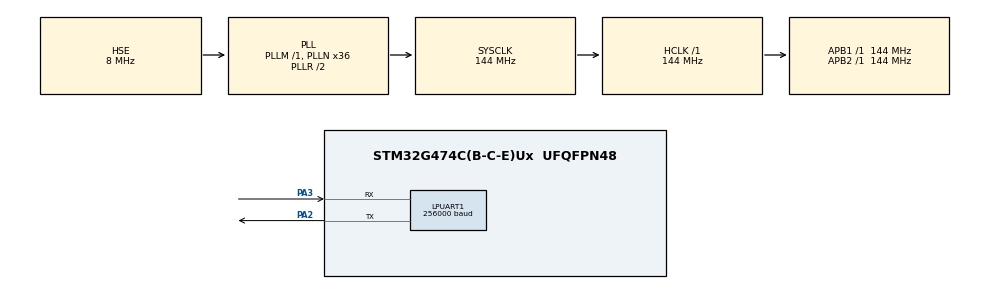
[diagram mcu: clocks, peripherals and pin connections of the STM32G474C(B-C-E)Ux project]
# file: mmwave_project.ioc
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Dma.LPUART1_RX.0.Direction=DMA_PERIPH_TO_MEMORY
Dma.LPUART1_RX.0.EventEnable=DISABLE
Dma.LPUART1_RX.0.Instance=DMA1_Channel1
Dma.LPUART1_RX.0.MemDataAlignment=DMA_MDATAALIGN_BYTE
Dma.LPUART1_RX.0.MemInc=DMA_MINC_ENABLE
Dma.LPUART1_RX.0.Mode=DMA_CIRCULAR
Dma.LPUART1_RX.0.PeriphDataAlignment=DMA_PDATAALIGN_BYTE
Dma.LPUART1_RX.0.PeriphInc=DMA_PINC_DISABLE
Dma.LPUART1_RX.0.Polarity=HAL_DMAMUX_REQ_GEN_RISING
Dma.LPUART1_RX.0.Priority=DMA_PRIORITY_LOW
Dma.LPUART1_RX.0.RequestNumber=1
Dma.LPUART1_RX.0.SignalID=NONE
Dma.LPUART1_RX.0.SyncEnable=DISABLE
Dma.LPUART1_RX.0.SyncPolarity=HAL_DMAMUX_SYNC_NO_EVENT
Dma.LPUART1_RX.0.SyncRequestNumber=1
Dma.LPUART1_RX.0.SyncSignalID=NONE
Dma.LPUART1_TX.1.Direction=DMA_MEMORY_TO_PERIPH
Dma.LPUART1_TX.1.EventEnable=DISABLE
Dma.LPUART1_TX.1.Instance=DMA1_Channel2
Dma.LPUART1_TX.1.MemDataAlignment=DMA_MDATAALIGN_BYTE
Dma.LPUART1_TX.1.MemInc=DMA_MINC_ENABLE
Dma.LPUART1_TX.1.Mode=DMA_NORMAL
Dma.LPUART1_TX.1.PeriphDataAlignment=DMA_PDATAALIGN_BYTE
Dma.LPUART1_TX.1.PeriphInc=DMA_PINC_DISABLE
Dma.LPUART1_TX.1.Polarity=HAL_DMAMUX_REQ_GEN_RISING
Dma.LPUART1_TX.1.Priority=DMA_PRIORITY_LOW
Dma.LPUART1_TX.1.RequestNumber=1
Dma.LPUART1_TX.1.SignalID=NONE
Dma.LPUART1_TX.1.SyncEnable=DISABLE
Dma.LPUART1_TX.1.SyncPolarity=HAL_DMAMUX_SYNC_NO_EVENT
Dma.LPUART1_TX.1.SyncRequestNumber=1
Dma.LPUART1_TX.1.SyncSignalID=NONE
Dma.Request0=LPUART1_RX
Dma.Request1=LPUART1_TX
LPUART1.BaudRate=256000
Mcu.Family=STM32G4
Mcu.Name=STM32G474C(B-C-E)Ux
Mcu.Package=UFQFPN48
NVIC.DMA1_Channel1_IRQn=true\:0\:0\:false\:false\:true\:false\:true\:true
NVIC.DMA1_Channel2_IRQn=true\:0\:0\:false\:false\:true\:false\:true\:true
NVIC.PriorityGroup=NVIC_PRIORITYGROUP_4
PA13.Mode=Serial_Wire
PA13.Signal=SYS_JTMS-SWDIO
PA14.Mode=Serial_Wire
PA14.Signal=SYS_JTCK-SWCLK
PA2.Mode=Asynchronous
PA2.Signal=LPUART1_TX
PA3.Mode=Asynchronous
PA3.Signal=LPUART1_RX
PF0-OSC_IN.Mode=HSE-External-Oscillator
PF0-OSC_IN.Signal=RCC_OSC_IN
PF1-OSC_OUT.Mode=HSE-External-Oscillator
PF1-OSC_OUT.Signal=RCC_OSC_OUT
ProjectManager.HeapSize=0x200
ProjectManager.StackSize=0x400
ProjectManager.TargetToolchain=STM32CubeIDE
RCC.ADC12Freq_Value=144000000
RCC.ADC345Freq_Value=144000000
RCC.AHBFreq_Value=144000000
RCC.APB1Freq_Value=144000000
RCC.APB1TimFreq_Value=144000000
RCC.APB2Freq_Value=144000000
RCC.APB2TimFreq_Value=144000000
RCC.CortexFreq_Value=144000000
RCC.EXTERNAL_CLOCK_VALUE=12288000
RCC.HCLKFreq_Value=144000000
RCC.HSE_VALUE=8000000
RCC.HSI48_VALUE=48000000
RCC.HSI_VALUE=16000000
RCC.LSE_VALUE=32768
RCC.PLLN=36
RCC.PLLSourceVirtual=RCC_PLLSOURCE_HSE
RCC.SYSCLKFreq_VALUE=144000000
RCC.SYSCLKSource=RCC_SYSCLKSOURCE_PLLCLK
RCC.USBFreq_Value=144000000
RCC.VCOOutputFreq_Value=288000000
VP_SYS_VS_DBSignals.Mode=DisableDeadBatterySignals
board=custom

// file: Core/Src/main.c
/* USER CODE BEGIN Header */
/**
  ******************************************************************************
  * @file           : main.c
  * @brief          : Main program body
  ******************************************************************************
  * @attention
  *
  * Copyright (c) 2024 STMicroelectronics.
  * All rights reserved.
  *
  * This software is licensed under terms that can be found in the LICENSE file
  * in the root directory of this software component.
  * If no LICENSE file comes with this software, it is provided AS-IS.
  *
  ******************************************************************************
  */
/* USER CODE END Header */
#include "main.h"
#include "dma.h"
#include "usart.h"
#include "gpio.h"

/* USER CODE BEGIN Includes */
#include "ld2450.h"

extern DMA_HandleTypeDef hdma_lpuart1_rx;
/* USER CODE END Includes */

void SystemClock_Config(void);

/* USER CODE BEGIN 0 */

comm_t comm_inst;

uint32_t rx_tick;

static void delay(uint32_t tick);
static void parseStart(int rx_start_index, int length);

int length_history_index = 0;
int length_history[200] = {0, };

/* USER CODE END 0 */

int main(void)
{

  /* MCU Configuration--------------------------------------------------------*/

  /* Reset of all peripherals, Initializes the Flash interface and the Systick. */
  HAL_Init();

  /* Configure the system clock */
  SystemClock_Config();

  /* Initialize all configured peripherals */
  MX_GPIO_Init();
  MX_DMA_Init();
  MX_LPUART1_UART_Init();
  /* USER CODE BEGIN 2 */

  HAL_UART_Receive_DMA(&hlpuart1, comm_inst.rx_buffer, DEF_RX_BUFFER_LENGTH);

  delay(10);
  comm_inst.rx_history = hdma_lpuart1_rx.Instance->CNDTR;
  initLd2450();
  rx_tick = HAL_GetTick();
  /* USER CODE END 2 */

  /* Infinite loop */
  while (1)
  {

    /* USER CODE BEGIN 3 */

	  if(comm_inst.rx_history != hdma_lpuart1_rx.Instance->CNDTR)
	  {
	      if(HAL_GetTick() - rx_tick > comm_inst.parse_period_tick_ms)
	      {
	          rx_tick = HAL_GetTick();
	          int rx_start = DEF_RX_BUFFER_LENGTH - comm_inst.rx_history;
	          int rx_length;
	          comm_inst.rx_history = hdma_lpuart1_rx.Instance->CNDTR;
	          rx_length = (DEF_RX_BUFFER_LENGTH + (DEF_RX_BUFFER_LENGTH - comm_inst.rx_history) - rx_start) % DEF_RX_BUFFER_LENGTH;
	          length_history[length_history_index] = rx_length;
	          if(length_history_index != 200)
	          {
	              length_history_index += 1;
	          }
	          parseStart(rx_start, rx_length);
	      }
	  }
	  else
	  {
	      rx_tick = HAL_GetTick();
	  }
  }
  /* USER CODE END 3 */
}

void SystemClock_Config(void)
{
  RCC_OscInitTypeDef RCC_OscInitStruct = {0};
  RCC_ClkInitTypeDef RCC_ClkInitStruct = {0};

  /** Configure the main internal regulator output voltage
  */
  HAL_PWREx_ControlVoltageScaling(PWR_REGULATOR_VOLTAGE_SCALE1);

  /** Initializes the RCC Oscillators according to the specified parameters
  * in the RCC_OscInitTypeDef structure.
  */
  RCC_OscInitStruct.OscillatorType = RCC_OSCILLATORTYPE_HSE;
  RCC_OscInitStruct.HSEState = RCC_HSE_ON;
  RCC_OscInitStruct.PLL.PLLState = RCC_PLL_ON;
  RCC_OscInitStruct.PLL.PLLSource = RCC_PLLSOURCE_HSE;
  RCC_OscInitStruct.PLL.PLLM = RCC_PLLM_DIV1;
  RCC_OscInitStruct.PLL.PLLN = 36;
  RCC_OscInitStruct.PLL.PLLP = RCC_PLLP_DIV2;
  RCC_OscInitStruct.PLL.PLLQ = RCC_PLLQ_DIV2;
  RCC_OscInitStruct.PLL.PLLR = RCC_PLLR_DIV2;
  if (HAL_RCC_OscConfig(&RCC_OscInitStruct) != HAL_OK)
  {
    Error_Handler();
  }

  /** Initializes the CPU, AHB and APB buses clocks
  */
  RCC_ClkInitStruct.ClockType = RCC_CLOCKTYPE_HCLK|RCC_CLOCKTYPE_SYSCLK
                              |RCC_CLOCKTYPE_PCLK1|RCC_CLOCKTYPE_PCLK2;
  RCC_ClkInitStruct.SYSCLKSource = RCC_SYSCLKSOURCE_PLLCLK;
  RCC_ClkInitStruct.AHBCLKDivider = RCC_SYSCLK_DIV1;
  RCC_ClkInitStruct.APB1CLKDivider = RCC_HCLK_DIV1;
  RCC_ClkInitStruct.APB2CLKDivider = RCC_HCLK_DIV1;

  if (HAL_RCC_ClockConfig(&RCC_ClkInitStruct, FLASH_LATENCY_4) != HAL_OK)
  {
    Error_Handler();
  }
}

/* USER CODE BEGIN 4 */

static void delay(uint32_t tick)
{
  uint32_t now_tick = HAL_GetTick();
  while(HAL_GetTick() - now_tick < tick)
  {

  }
}

static void parseStart(int rx_start_index, int length)
{
    for(int i = rx_start_index; i <= length; i++)
    {
        int index_buff = i %= DEF_RX_BUFFER_LENGTH;

        switch(comm_inst.rx_buffer[index_buff])
        {
            case 0xFD:  // command header 0
                break;
            case 0xFC:  // command header 1
                break;
            case 0xFB:  // command header 2
                break;
            case 0xFA:  // command header 3
                break;
            case 0x04:  // command end 0
                break;
            case 0x03:  // command end 1,   // radar data head 2
                break;
            case 0x02:  // command end 2
                break;
            case 0x01:  // command end 3
                break;
            case 0xAA:  // radar data head 0
                break;
            case 0xFF:  // radar data head 1
                break;
            case 0x00:  // radar data head 3
                break;
            case 0x55:  // radar data end 0
                break;
            case 0xCC:  // radar data end 1
                break;
            default:
                break;
        }
    }
}
/* USER CODE END 4 */

void Error_Handler(void)
{
  __disable_irq();
  while (1)
  {
  }
}
